# SAMA7G54D2G device description
Architecture: CORTEX-A7; Family: SAMA; Series: SAMA7G
Registers are 32-bit, read-write, reset 0x0 unless marked. A register's access mark holds for its fields unless they carry their own. Offsets are from the block's base; [hi:lo] are bit positions; 'fields as' and 'values as' point back to an identical list.

## DWDT — Dual Watchdog Timer
Instances: DWDT 0xE001C000
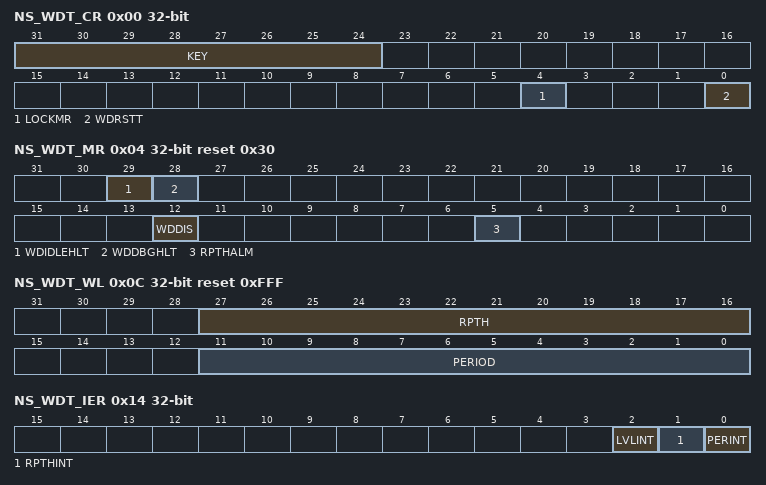
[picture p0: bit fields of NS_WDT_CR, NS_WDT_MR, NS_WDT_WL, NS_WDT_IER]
0x00 NS_WDT_CR wo reset not defined — Never Secure Control Register
  [31:24] KEY — Password
    165=PASSWD (Writing any other value in this field aborts the write operation.)
  [4] LOCKMR — Lock Mode Register Write Access
    0=No effect; 1=Locks the configuration registers if KEY is written to 0xA5. Write accesses to NS_WDT_MR, NS_WDT_VR, NS_WDT_WL and NS_WDT_IL have no effect.
  [0] WDRSTT — Watchdog Restart
    0=No effect; 1=Restarts the watchdog if KEY is written to 0xA5
0x04 NS_WDT_MR reset 0x30 — Never Secure Mode Register
  [29] WDIDLEHLT — Watchdog Idle Halt
    0=The watchdog runs when the system is in Idle state; 1=The watchdog stops when the system is in Idle state
  [28] WDDBGHLT — Watchdog Debug Halt
    0=The watchdog runs when the processor is in Debug state; 1=The watchdog stops when the processor is in Debug state
  [12] WDDIS — Watchdog Disable
    0=Enables the Watchdog Timer; 1=Disables the Watchdog Timer
  [5] RPTHALM — Repeat Threshold Alarm
    0=No alarm is sent to the security module if the watchdog is restarted before the RPTH threshold; 1=An alarm is sent to the security module if the watchdog is restarted before the RPTH threshold
0x08 NS_WDT_VR ro reset 0xFFF — Never Secure Value Register
  [11:0] COUNTER — Watchdog Down Counter Value
0x0C NS_WDT_WL reset 0xFFF — Never Secure Window Level Register
  [27:16] RPTH — Repeat Threshold
  [11:0] PERIOD — Watchdog Period
0x10 NS_WDT_IL reset 0xFFF — Never Secure Interrupt Level Register
  [11:0] LVLTH — Level Threshold
0x14 NS_WDT_IER wo reset not defined (atomic set of NS_WDT_IMR) — Never Secure Interrupt Enable Register
  [2] LVLINT — Interrupt Level Threshold Interrupt Enable
    0=No effect; 1=The never secure interrupt threshold failure interrupt is enabled
  [1] RPTHINT — Repeat Threshold Interrupt Enable
    0=No effect; 1=The never secure repeat threshold failure interrupt is enabled
  [0] PERINT — Period Interrupt Enable
    0=No effect; 1=The never secure period failure interrupt is enabled
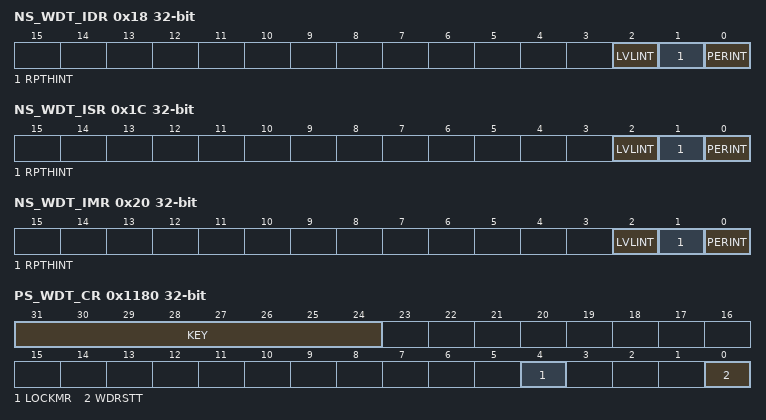
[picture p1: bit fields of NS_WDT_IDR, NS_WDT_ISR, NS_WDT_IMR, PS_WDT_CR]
0x18 NS_WDT_IDR wo reset not defined (atomic clear of NS_WDT_IMR) — Never Secure Interrupt Disable Register
  [2] LVLINT — Interrupt Level Threshold Interrupt Disable
    0=No effect; 1=The never secure interrupt threshold failure interrupt is disabled
  [1] RPTHINT — Repeat Threshold Interrupt Disable
    0=No effect; 1=The never secure repeat threshold failure interrupt is disabled
  [0] PERINT — Period Interrupt Disable
    0=No effect; 1=The never secure period failure interrupt is disabled
0x1C NS_WDT_ISR ro — Never Secure Interrupt Status Register
  [2] LVLINT — Interrupt Level Threshold Interrupt Enable
    0=No level threshold failure has occurred in the never secure watchdog since the last read of NS_WDT_ISR; 1=At least one level threshold failure has occurred in the never secure watchdog since the last read of NS_WDT_ISR
  [1] RPTHINT — Repeat Threshold Interrupt Enable
    0=No repeat threshold failure has occurred in the never secure watchdog since the last read of NS_WDT_ISR; 1=At least one repeat threshold failure has occurred in the never secure watchdog since the last read of NS_WDT_ISR
  [0] PERINT — Period Interrupt Status
    0=No period failure has occurred in the never secure watchdog since the last read of NS_WDT_ISR; 1=At least one period failure has occurred in the never secure watchdog since the last read of NS_WDT_ISR
0x20 NS_WDT_IMR ro — Never Secure Interrupt Mask Register
  [2] LVLINT — Interrupt Level Threshold Interrupt Mask
    0=Interrupt on LVLINT is disabled; 1=Interrupt on LVLINT is enabled
  [1] RPTHINT — Repeat Threshold Interrupt Mask
    0=Interrupt on RPTHINT is disabled; 1=Interrupt on RPTHINT is enabled
  [0] PERINT — Period Interrupt Mask
    0=Interrupt on PERINT is disabled; 1=Interrupt on PERINT is enabled
0x1180 PS_WDT_CR wo reset not defined — Programmable Secure Control Register
  [31:24] KEY — Password
    values as NS_WDT_CR.KEY
  [4] LOCKMR — Lock Mode Register Write Access
    0=No effect; 1=Locks the configuration registers if KEY is written to 0xA5. Write accesses to PS_WDT_MR, PS_WDT_VR, PS_WDT_WL and PS_WDT_IL have no effect.
  [0] WDRSTT — Watchdog Restart
    values as NS_WDT_CR.WDRSTT
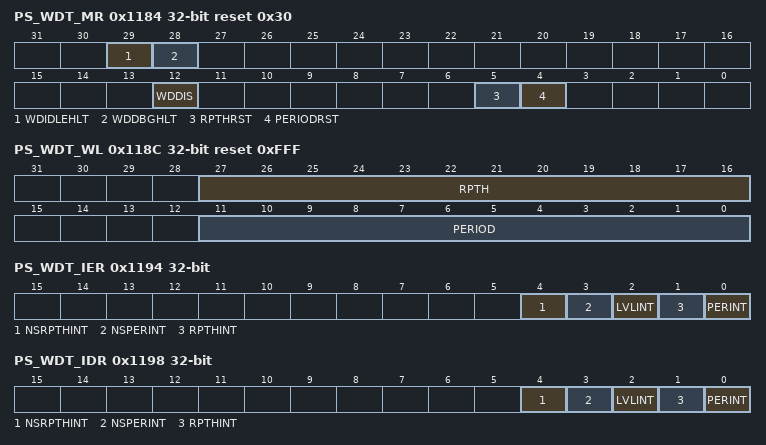
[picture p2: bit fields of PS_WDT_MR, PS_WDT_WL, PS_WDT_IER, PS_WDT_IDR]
0x1184 PS_WDT_MR reset 0x30 — Programmable Secure Mode Register
  [29] WDIDLEHLT — Watchdog Idle Halt
    values as NS_WDT_MR.WDIDLEHLT
  [28] WDDBGHLT — Watchdog Debug Halt
    values as NS_WDT_MR.WDDBGHLT
  [12] WDDIS — Watchdog Disable
    0=Enables the Watchdog Timer; 1=Disables the Watchdog Timer
  [5] RPTHRST — Repeat Threshold Reset
    0=No reset is generated if the watchdog is restarted before the RPTH threshold; 1=A reset is generated if the watchdog is restarted before the RPTH threshold
  [4] PERIODRST — Period Reset
    0=No reset is generated if the watchdog down counter reaches 0; 1=A reset is generated once the watchdog down counter reaches 0
0x1188 PS_WDT_VR ro — Programmable Secure Value Register
  [11:0] COUNTER — Watchdog Down Counter Value
0x118C PS_WDT_WL reset 0xFFF — Programmable Secure Window Level
  [27:16] RPTH — Repeat Threshold
  [11:0] PERIOD — Watchdog Period
0x1190 PS_WDT_IL reset 0xFFF — Programmable Secure Interrupt Level
  [11:0] LVLTH — Level Threshold
0x1194 PS_WDT_IER wo reset not defined (atomic set of PS_WDT_IMR) — Programmable Secure Interrupt Enable Register
  [4] NSRPTHINT — Never Secure Repeat Threshold Interrupt Enable
    0=No effect; 1=A never secure repeat threshold failure generates an interrupt in the programmable secure area
  [3] NSPERINT — Never Secure Period Interrupt Enable
    0=No effect; 1=A never secure period failure generates an interrupt in the programmable secure area
  [2] LVLINT — Interrupt Level Threshold Interrupt Enable
    0=No effect; 1=The programmable secure interrupt threshold failure interrupt is enabled
  [1] RPTHINT — Repeat Threshold Interrupt Enable
    0=No effect; 1=The programmable secure repeat threshold failure interrupt is enabled
  [0] PERINT — Period Interrupt Enable
    0=No effect; 1=The programmable secure period failure interrupt is enabled
0x1198 PS_WDT_IDR wo reset not defined (atomic clear of PS_WDT_IMR) — Programmable Secure Interrupt Disable Register
  [4] NSRPTHINT — Never Secure Repeat Threshold Interrupt Disable
    0=No effect; 1=A never secure repeat threshold failure does not generate an interrupt in the programmable secure area
  [3] NSPERINT — Never Secure Period Interrupt Disable
    0=No effect; 1=A never secure period failure does not generate an interrupt in the programmable secure area
  [2] LVLINT — Interrupt Level Threshold Interrupt Disable
    0=No effect; 1=The Programmable secure interrupt threshold failure interrupt is disabled
  [1] RPTHINT — Repeat Threshold Interrupt Disable
    0=No effect; 1=The Programmable secure repeat threshold failure interrupt is disabled
  [0] PERINT — Period Interrupt Disable
    0=No effect; 1=The Programmable secure period failure interrupt is disabled
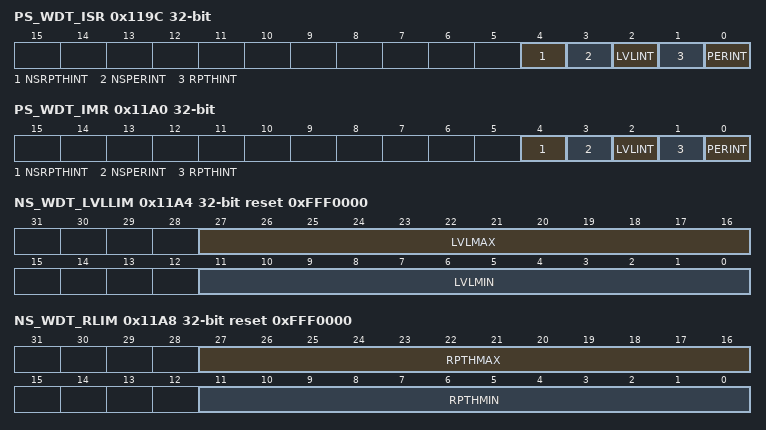
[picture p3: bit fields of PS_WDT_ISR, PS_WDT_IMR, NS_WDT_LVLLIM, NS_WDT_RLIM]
0x119C PS_WDT_ISR ro — Programmable Secure Interrupt Status Register
  [4] NSRPTHINT — Never Secure Repeat Threshold Interrupt Status
    0=No never secure repeat threshold failure has occurred in the programmable secure watchdog since the last read of PS_WDT_ISR; 1=At least one never secure repeat threshold failure occurred in the programmable secure watchdog since the last read of PS_WDT_ISR
  [3] NSPERINT — Never Secure Period Interrupt Status
    0=No never secure period failure has occurred in the programmable secure watchdog since the last read of PS_WDT_ISR; 1=At least one never secure period failure occurred in the programmable secure watchdog since the last read of PS_WDT_ISR
  [2] LVLINT — Interrupt Level Threshold Interrupt Status
    0=No level threshold failure has occurred in the Programmable secure watchdog since the last read of PS_WDT_ISR; 1=At least one level threshold failure has occurred in the Programmable secure watchdog since the last read of PS_WDT_ISR
  [1] RPTHINT — Repeat Threshold Interrupt Status
    0=No repeat threshold failure has occurred in the Programmable secure watchdog since the last read of PS_WDT_ISR; 1=At least one repeat threshold failure has occurred in the Programmable secure watchdog since the last read of PS_WDT_ISR
  [0] PERINT — Period Interrupt Status
    0=No period failure has occurred in the Programmable secure watchdog since the last read of PS_WDT_ISR; 1=At least one period failure has occurred in the Programmable secure watchdog since the last read of PS_WDT_ISR
0x11A0 PS_WDT_IMR ro — Programmable Secure Interrupt Mask Register
  [4] NSRPTHINT — Never Secure Repeat Threshold Interrupt Mask
    0=Programmable secure interrupt on never secure RPTHINT interrupt is disabled; 1=Programmable secure interrupt on never secure RPTHINT interrupt is enabled
  [3] NSPERINT — Never Secure Period Interrupt Mask
    0=Programmable secure interrupt on never secure PERINT interrupt is disabled; 1=Programmable secure interrupt on never secure PERINT interrupt is enabled
  [2] LVLINT — Interrupt Level Threshold Interrupt Mask
    values as NS_WDT_IMR.LVLINT
  [1] RPTHINT — Repeat Threshold Interrupt Mask
    values as NS_WDT_IMR.RPTHINT
  [0] PERINT — Period Interrupt Mask
    values as NS_WDT_IMR.PERINT
0x11A4 NS_WDT_LVLLIM reset 0xFFF0000 — Never Secure Level Limits Register
  [27:16] LVLMAX — Level Maximum
  [11:0] LVLMIN — Level Minimum
0x11A8 NS_WDT_RLIM reset 0xFFF0000 — Never Secure Repeat Limits Register
  [27:16] RPTHMAX — Repeat Threshold Maximum
  [11:0] RPTHMIN — Repeat Threshold Minimum
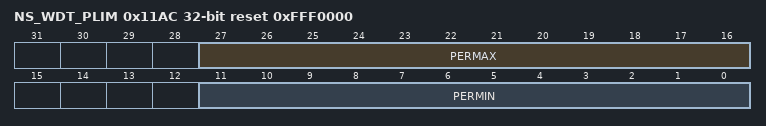
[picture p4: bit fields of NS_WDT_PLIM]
0x11AC NS_WDT_PLIM reset 0xFFF0000 — Never Secure Period Limits Register
  [27:16] PERMAX — Period Maximum
  [11:0] PERMIN — Period Minimum

## Notices in the file
Copyright (c) 2020 Microchip Technology Inc.
SPDX-License-Identifier: Apache-2.0
Licensed under the Apache License, Version 2.0 (the "License");
you may not use this file except in compliance with the License.
You may obtain a copy of the License at
http://www.apache.org/licenses/LICENSE-2.0
Unless required by applicable law or agreed to in writing, software
distributed under the License is distributed on an "AS IS" BASIS,
WITHOUT WARRANTIES OR CONDITIONS OF ANY KIND, either express or implied.
See the License for the specific language governing permissions and
limitations under the License.
